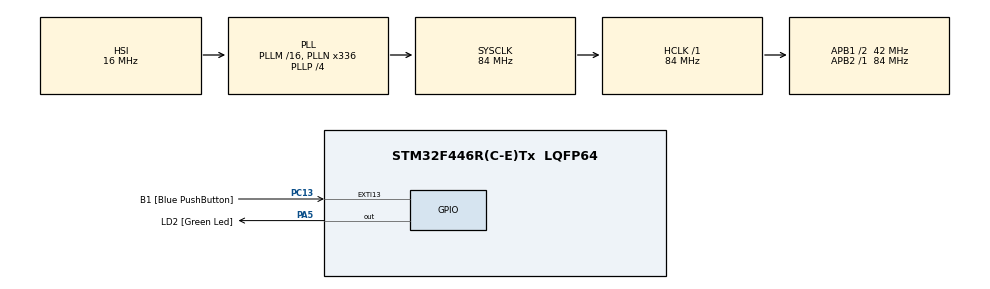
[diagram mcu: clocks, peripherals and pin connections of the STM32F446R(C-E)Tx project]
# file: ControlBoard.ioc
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Mcu.Family=STM32F4
Mcu.Name=STM32F446R(C-E)Tx
Mcu.Package=LQFP64
NVIC.PriorityGroup=NVIC_PRIORITYGROUP_0
PA13.GPIO_Label=TMS
PA13.Signal=SYS_JTMS-SWDIO
PA14.GPIO_Label=TCK
PA14.Signal=SYS_JTCK-SWCLK
PA2.GPIO_Label=USART_TX
PA2.Signal=USART2_TX
PA3.GPIO_Label=USART_RX
PA3.Signal=USART2_RX
PA5.GPIO_Label=LD2 [Green Led]
PA5.Signal=GPIO_Output
PB3.GPIO_Label=SWO
PB3.Signal=SYS_JTDO-SWO
PC13.GPIO_Label=B1 [Blue PushButton]
PC13.GPIO_ModeDefaultEXTI=GPIO_MODE_IT_FALLING
PC13.Signal=GPXTI13
PC14-OSC32_IN.Signal=RCC_OSC32_IN
PC15-OSC32_OUT.Signal=RCC_OSC32_OUT
PH0-OSC_IN.Signal=RCC_OSC_IN
PH1-OSC_OUT.Signal=RCC_OSC_OUT
ProjectManager.HeapSize=0x200
ProjectManager.StackSize=0x400
ProjectManager.TargetToolchain=STM32CubeIDE
RCC.AHBFreq_Value=84000000
RCC.APB1CLKDivider=RCC_HCLK_DIV2
RCC.APB1Freq_Value=42000000
RCC.APB1TimFreq_Value=84000000
RCC.APB2Freq_Value=84000000
RCC.APB2TimFreq_Value=84000000
RCC.CortexFreq_Value=84000000
RCC.FLatency-AdvancedSettings=FLASH_LATENCY_2
RCC.HCLKFreq_Value=84000000
RCC.HSE_VALUE=8000000
RCC.HSI_VALUE=16000000
RCC.LSE_VALUE=32768
RCC.PLLN=336
RCC.PLLP=RCC_PLLP_DIV4
RCC.SYSCLKFreq_VALUE=84000000
RCC.SYSCLKSource=RCC_SYSCLKSOURCE_PLLCLK
RCC.USBFreq_Value=168000000
RCC.VCOOutputFreq_Value=336000000
board=NUCLEO-F446RE

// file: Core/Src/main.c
/* USER CODE BEGIN Header */
/**
  ******************************************************************************
  * @file           : main.c
  * @brief          : Main program body
  ******************************************************************************
  * @attention
  *
  * Copyright (c) 2025 STMicroelectronics.
  * All rights reserved.
  *
  * This software is licensed under terms that can be found in the LICENSE file
  * in the root directory of this software component.
  * If no LICENSE file comes with this software, it is provided AS-IS.
  *
  ******************************************************************************
  */
/* USER CODE END Header */
#include <UART1.h>
#include "main.h"
#include "Delay.h"
#include "OLED.h"
#include "Timer.h"
#include "pid.h"
#include "Motor.h"
#include "math.h"
#include "Encoder.h"
#include "UART2.h"
#include "ADC.h"

#include "PWM2.h"
#include "PWM4.h"
/* USER CODE BEGIN Includes */
#define TICKS_PER_REV 4680.0f //13*4*90
#define Sample_time   0.01f // 控制週期 10ms

#define PWM_MAX 1000

/* USER CODE END Includes */

void SystemClock_Config(void);

/* USER CODE BEGIN PFP */
PIDController wheel1,wheel2,wheel3,wheel4;

typedef struct{
	float speed1,speed2,speed3,speed4;
}Encoder;
Encoder WheelSpeed;

//For wheel1，負為向前
float wheel1_motor_rpm;
float wheel1_speed = -10;

int16_t wheel1_last_count = 0;
int16_t wheel1_current = 0;
int16_t wheel1_delta = 0;
uint16_t wheel1_count;
float wheel1_motor_rps = 0;
float wheel1_out ;

//For wheel2，正為向前
float wheel2_motor_rpm;
float wheel2_speed = 10;

int16_t wheel2_last_count = 0;
int16_t wheel2_current = 0;
int16_t wheel2_delta = 0;
uint16_t wheel2_count;
float wheel2_motor_rps = 0;
float wheel2_out ;

//For wheel3，正為向前
float wheel3_motor_rpm;
float wheel3_speed = 10;

int16_t wheel3_last_count = 0;
int16_t wheel3_current = 0;
int16_t wheel3_delta = 0;
uint16_t wheel3_count;
float wheel3_motor_rps = 0;
float wheel3_out ;

//For wheel4，負為向前
float wheel4_motor_rpm;
float wheel4_speed = -30;

int16_t wheel4_last_count = 0;
int16_t wheel4_current = 0;
int16_t wheel4_delta = 0;
uint16_t wheel4_count;
float wheel4_motor_rps = 0;
float wheel4_out ;

int x = 0;

//For 運動學算法
float Vx = 0;
float Vy = 0;
float Wz = 0;
float alpha = 2;

//Check BLE
uint16_t a;
uint16_t s;
uint16_t d;

//JointSitck 中心點校正
uint8_t FirstJoint = 1;
uint16_t Vx_central,Vy_central,Wz_central;
float max_Lspeed = 30;
float max_Rspeed = 10;

uint8_t RxState = 0;
/* USER CODE END PFP */

/* USER CODE BEGIN 0 */
uint16_t y = 0;
float z,w;

/* USER CODE END 0 */

int main(void)
{

  /* MCU Configuration--------------------------------------------------------*/

  /* Reset of all peripherals, Initializes the Flash interface and the Systick. */
  HAL_Init();

  /* Configure the system clock */
  SystemClock_Config();

  /* Initialize all configured peripherals */
  /* USER CODE BEGIN 2 */
  /*模块初始化*/
	OLED_Init();		//OLED初始化
	Timer_Init();
	Motor_Init();

	Serial_Init();		//串口初始化
	JoinStick_Init();
//	AD_Init();
//	Encoder_Init();

	OLED_ShowString(1, 1, "TIM1:");
	OLED_ShowString(2, 1, "TIM2:");
	OLED_ShowString(3, 1, "TIM3:");
	OLED_ShowString(4, 1, "TIM4:");

	// 30RPM下 Kp = 2 Ki = 0.1 Kd = 0.02 good
	//wheel1
	wheel1.param.Kp = 1.5;
	wheel1.param.Ki = 0.15 / wheel1.param.Kp  ;
	wheel1.param.Kd = 0.03 / wheel1.param.Kp ;
	wheel1.param.Kr = 1.0f;
	wheel1.param.Umax = 200.0f;
	wheel1.param.Umin = -200.0f;
	wheel1.term.c1 = 0.1f;  // D 濾波器
	wheel1.term.c2 = 0.9f;

	//wheel2
	wheel2.param.Kp = 1.5;
	wheel2.param.Ki = 0.15 / wheel2.param.Kp  ;
	wheel2.param.Kd = 0.03 / wheel2.param.Kp ;
	wheel2.param.Kr = 1.0f;
	wheel2.param.Umax = 200.0f;
	wheel2.param.Umin = -200.0f;
	wheel2.term.c1 = 0.1f;  // D 濾波器
	wheel2.term.c2 = 0.9f;

	//wheel3
	wheel3.param.Kp = 1.5;
	wheel3.param.Ki = 0.15 / wheel3.param.Kp  ;
	wheel3.param.Kd = 0.03 / wheel3.param.Kp ;
	wheel3.param.Kr = 1.0f;
	wheel3.param.Umax = 200.0f;
	wheel3.param.Umin = -200.0f;
	wheel3.term.c1 = 0.1f;  // D 濾波器
	wheel3.term.c2 = 0.9f;

	//wheel4
	wheel4.param.Kp = 1.5;
	wheel4.param.Ki = 0.15 / wheel4.param.Kp  ;
	wheel4.param.Kd = 0.03 / wheel4.param.Kp ;
	wheel4.param.Kr = 1.0f;
	wheel4.param.Umax = 200.0f;
	wheel4.param.Umin = -200.0f;
	wheel4.term.c1 = 0.1f;  // D 濾波器
	wheel4.term.c2 = 0.9f;

  /* USER CODE END 2 */

  /* Infinite loop */
  while (1)
  {
//	  y = TIM4->CNT;
//	  PWM2_SetCompare1(1000);
//	  PWM4_SetCompare1(1000);
//    AD_GetValue();
//    Delay_ms(100);
	if(Serial_RxFlag == 1)
	{
		OLED_ShowNum(1, 7, Serial_RxPacket[0], 5);	//不断刷新显示编码器测得的最新速度
		OLED_ShowNum(2, 7, Serial_RxPacket[1], 5);	//不断刷新显示编码器测得的最新速度
		OLED_ShowNum(3, 7, Serial_RxPacket[2], 5);	//不断刷新显示编码器测得的最新速度
		OLED_ShowNum(4, 7, Serial_RxPacket[3], 5);	//不断刷新显示编码器测得的最新速度
	}

	if(JoinStickFlag == 1 && FirstJoint == 1)
	{
		Vx_central = JoinStick[0];
		Vy_central = JoinStick[1];
		Wz_central = JoinStick[2];
		FirstJoint = 0;
	}

//	Motor_SetSpeed(1,y,x);
//	Motor_SetSpeed(2,z,w);
//	Motor_SetSpeed(3,y,x);
//	Motor_SetSpeed(4,z,w);

  }
}

void EncoderSpeed(void)
{
	//wheel1
	wheel1_count = Serial_RxPacket[0];
	wheel1_current = (int16_t)wheel1_count;
	wheel1_delta = (int16_t)((uint16_t)wheel1_current - (uint16_t)wheel1_last_count);
	wheel1_last_count = wheel1_current;

	wheel1_motor_rps = (wheel1_delta / TICKS_PER_REV) / Sample_time ;
	wheel1_motor_rpm = wheel1_motor_rps * 60;
	WheelSpeed.speed1 = wheel1_motor_rpm;

	//wheel2
	wheel2_count = Serial_RxPacket[1];
	wheel2_current = (int16_t)wheel2_count;
	wheel2_delta = (int16_t)((uint16_t)wheel2_current - (uint16_t)wheel2_last_count);
	wheel2_last_count = wheel2_current;

	wheel2_motor_rps = (wheel2_delta / TICKS_PER_REV) / Sample_time ;
	wheel2_motor_rpm = wheel2_motor_rps * 60;
	WheelSpeed.speed2 = wheel2_motor_rpm;

	//wheel3
	wheel3_count = Serial_RxPacket[2];
	wheel3_current = (int16_t)wheel3_count;
	wheel3_delta = (int16_t)((uint16_t)wheel3_current - (uint16_t)wheel3_last_count);
	wheel3_last_count = wheel3_current;

	wheel3_motor_rps = (wheel3_delta / TICKS_PER_REV) / Sample_time ;
	wheel3_motor_rpm = wheel3_motor_rps * 60;
	WheelSpeed.speed3 = wheel3_motor_rpm;

	//wheel4
	wheel4_count = Serial_RxPacket[3];
	wheel4_current = (int16_t)wheel4_count;
	wheel4_delta = (int16_t)((uint16_t)wheel4_current - (uint16_t)wheel4_last_count);
	wheel4_last_count = wheel4_current;

	wheel4_motor_rps = (wheel4_delta / TICKS_PER_REV) / Sample_time ;
	wheel4_motor_rpm = wheel4_motor_rps * 60;
	WheelSpeed.speed4 = wheel4_motor_rpm;
}

void TIM8_BRK_TIM12_IRQHandler(void)
{
	if (TIM12->SR & (1 << 0))
	{
		Serial_SendByte(0x01);

		if(Serial_RxFlag == 1 && FirstJoint == 0)
		{
			EncoderSpeed();
			x ++;

			Vx = -((float)(JoinStick[0] - Vx_central) / (float)Vx_central) * max_Lspeed;
			Vy =  ((float)(JoinStick[1] - Vy_central) / (float)Vy_central) * max_Lspeed;

			if( (JoinStick[2] - Wz_central) > -1000 && (JoinStick[2] - Wz_central) < 1000 )
				Wz = 0;
			else
				Wz =  ((float)(JoinStick[2] - Wz_central) / (float)Wz_central) * max_Rspeed;

			Wz = -Wz;

			wheel1_speed = Vx + Vy + alpha * Wz; //front right
			wheel2_speed = Vx - Vy - alpha * Wz; //front left
			wheel3_speed = Vx + Vy - alpha * Wz; //rear  left
			wheel4_speed = Vx - Vy + alpha * Wz; //rear  right
//
//
			wheel1_speed = -wheel1_speed;
			wheel2_speed = -wheel2_speed;
			wheel3_speed = -wheel3_speed;
			wheel4_speed = -wheel4_speed;

			wheel1.term.Ref = wheel1_speed;
			wheel1.term.Fbk = WheelSpeed.speed1;

			wheel2.term.Ref = wheel2_speed;
			wheel2.term.Fbk = WheelSpeed.speed2;

			wheel3.term.Ref = wheel3_speed;
			wheel3.term.Fbk = WheelSpeed.speed3;

			wheel4.term.Ref = wheel4_speed;
			wheel4.term.Fbk = WheelSpeed.speed4;

			float wheel1_output = PID_Update(&wheel1);
			float wheel3_output = PID_Update(&wheel3);
			float wheel2_output = PID_Update(&wheel2);
			float wheel4_output = PID_Update(&wheel4);

			wheel1_out = wheel1_output;
			wheel3_out = wheel3_output;
			wheel2_out = wheel2_output;
			wheel4_out = wheel4_output;

			int wheel1_pwm = (int)(fabs(wheel1_out) / 200.0f * PWM_MAX);
			int wheel3_pwm = (int)(fabs(wheel3_out) / 200.0f * PWM_MAX);
			int wheel2_pwm = (int)(fabs(wheel2_out) / 200.0f * PWM_MAX);
			int wheel4_pwm = (int)(fabs(wheel4_out) / 200.0f * PWM_MAX);

			if (wheel1_pwm > PWM_MAX) wheel1_pwm = PWM_MAX;
			if (wheel3_pwm > PWM_MAX) wheel3_pwm = PWM_MAX;
			if (wheel2_pwm > PWM_MAX) wheel2_pwm = PWM_MAX;
			if (wheel4_pwm > PWM_MAX) wheel4_pwm = PWM_MAX;

			Motor_SetSpeed(1,wheel1_pwm,wheel1_output);  // 設定 PWM duty
			Motor_SetSpeed(3,wheel3_pwm,wheel3_output);  // 設定 PWM duty
			Motor_SetSpeed(2,wheel2_pwm,wheel2_output);  // 設定 PWM duty
			Motor_SetSpeed(4,wheel4_pwm,wheel4_output);  // 設定 PWM duty

			Serial_RxFlag = 0;
		}

		TIM12->SR &= ~(1 << 0);
	}
}

void SystemClock_Config(void)
{
  RCC_OscInitTypeDef RCC_OscInitStruct = {0};
  RCC_ClkInitTypeDef RCC_ClkInitStruct = {0};

  /** Configure the main internal regulator output voltage
  */
  __HAL_RCC_PWR_CLK_ENABLE();
  __HAL_PWR_VOLTAGESCALING_CONFIG(PWR_REGULATOR_VOLTAGE_SCALE3);

  /** Initializes the RCC Oscillators according to the specified parameters
  * in the RCC_OscInitTypeDef structure.
  */
  RCC_OscInitStruct.OscillatorType = RCC_OSCILLATORTYPE_HSI;
  RCC_OscInitStruct.HSIState = RCC_HSI_ON;
  RCC_OscInitStruct.HSICalibrationValue = RCC_HSICALIBRATION_DEFAULT;
  RCC_OscInitStruct.PLL.PLLState = RCC_PLL_ON;
  RCC_OscInitStruct.PLL.PLLSource = RCC_PLLSOURCE_HSI;
  RCC_OscInitStruct.PLL.PLLM = 16;
  RCC_OscInitStruct.PLL.PLLN = 336;
  RCC_OscInitStruct.PLL.PLLP = RCC_PLLP_DIV4;
  RCC_OscInitStruct.PLL.PLLQ = 2;
  RCC_OscInitStruct.PLL.PLLR = 2;
  if (HAL_RCC_OscConfig(&RCC_OscInitStruct) != HAL_OK)
  {
    Error_Handler();
  }

  /** Initializes the CPU, AHB and APB buses clocks
  */
  RCC_ClkInitStruct.ClockType = RCC_CLOCKTYPE_HCLK|RCC_CLOCKTYPE_SYSCLK
                              |RCC_CLOCKTYPE_PCLK1|RCC_CLOCKTYPE_PCLK2;
  RCC_ClkInitStruct.SYSCLKSource = RCC_SYSCLKSOURCE_PLLCLK;
  RCC_ClkInitStruct.AHBCLKDivider = RCC_SYSCLK_DIV1;
  RCC_ClkInitStruct.APB1CLKDivider = RCC_HCLK_DIV2;
  RCC_ClkInitStruct.APB2CLKDivider = RCC_HCLK_DIV1;

  if (HAL_RCC_ClockConfig(&RCC_ClkInitStruct, FLASH_LATENCY_2) != HAL_OK)
  {
    Error_Handler();
  }
}

void Error_Handler(void)
{
  __disable_irq();
  while (1)
  {
  }
}
